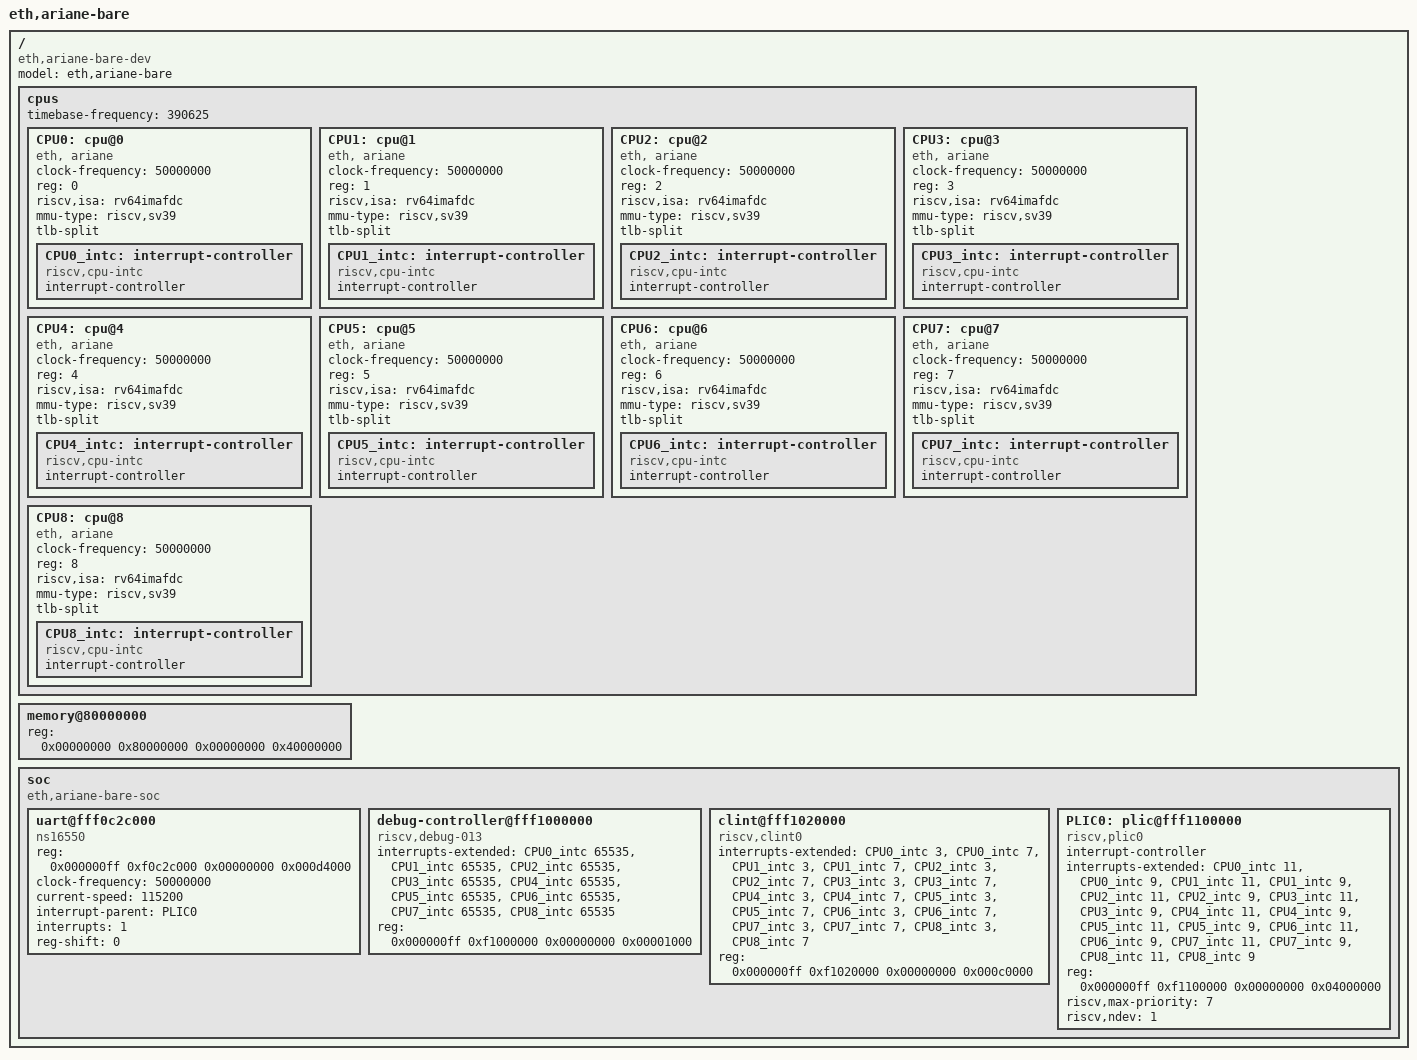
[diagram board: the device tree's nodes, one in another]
// DTS generated with gen_riscv_dts(...)
// OpenPiton + Ariane framework
// Date: Nov 05 2021 09:18:08

/dts-v1/;

/ {
    #address-cells = <2>;
    #size-cells = <2>;
    compatible = "eth,ariane-bare-dev";
    model = "eth,ariane-bare";
    // TODO: interrupt-based UART is currently very slow
    // with this configuration. this needs to be fixed.
    // chosen {
    //     stdout-path = "/soc/uart@fff0c2c000:115200";
    // };
    cpus {
        #address-cells = <1>;
        #size-cells = <0>;
        timebase-frequency = <390625>;
    
        CPU0: cpu@0 {
            clock-frequency = <50000000>;
            device_type = "cpu";
            reg = <0>;
            status = "okay";
            compatible = "eth, ariane", "riscv";
            riscv,isa = "rv64imafdc";
            mmu-type = "riscv,sv39";
            tlb-split;
            // HLIC - hart local interrupt controller
            CPU0_intc: interrupt-controller {
                #interrupt-cells = <1>;
                interrupt-controller;
                compatible = "riscv,cpu-intc";
            };
        };
        
        CPU1: cpu@1 {
            clock-frequency = <50000000>;
            device_type = "cpu";
            reg = <1>;
            status = "okay";
            compatible = "eth, ariane", "riscv";
            riscv,isa = "rv64imafdc";
            mmu-type = "riscv,sv39";
            tlb-split;
            // HLIC - hart local interrupt controller
            CPU1_intc: interrupt-controller {
                #interrupt-cells = <1>;
                interrupt-controller;
                compatible = "riscv,cpu-intc";
            };
        };
        
        CPU2: cpu@2 {
            clock-frequency = <50000000>;
            device_type = "cpu";
            reg = <2>;
            status = "okay";
            compatible = "eth, ariane", "riscv";
            riscv,isa = "rv64imafdc";
            mmu-type = "riscv,sv39";
            tlb-split;
            // HLIC - hart local interrupt controller
            CPU2_intc: interrupt-controller {
                #interrupt-cells = <1>;
                interrupt-controller;
                compatible = "riscv,cpu-intc";
            };
        };
        
        CPU3: cpu@3 {
            clock-frequency = <50000000>;
            device_type = "cpu";
            reg = <3>;
            status = "okay";
            compatible = "eth, ariane", "riscv";
            riscv,isa = "rv64imafdc";
            mmu-type = "riscv,sv39";
            tlb-split;
            // HLIC - hart local interrupt controller
            CPU3_intc: interrupt-controller {
                #interrupt-cells = <1>;
                interrupt-controller;
                compatible = "riscv,cpu-intc";
            };
        };
        
        CPU4: cpu@4 {
            clock-frequency = <50000000>;
            device_type = "cpu";
            reg = <4>;
            status = "okay";
            compatible = "eth, ariane", "riscv";
            riscv,isa = "rv64imafdc";
            mmu-type = "riscv,sv39";
            tlb-split;
            // HLIC - hart local interrupt controller
            CPU4_intc: interrupt-controller {
                #interrupt-cells = <1>;
                interrupt-controller;
                compatible = "riscv,cpu-intc";
            };
        };
        
        CPU5: cpu@5 {
            clock-frequency = <50000000>;
            device_type = "cpu";
            reg = <5>;
            status = "okay";
            compatible = "eth, ariane", "riscv";
            riscv,isa = "rv64imafdc";
            mmu-type = "riscv,sv39";
            tlb-split;
            // HLIC - hart local interrupt controller
            CPU5_intc: interrupt-controller {
                #interrupt-cells = <1>;
                interrupt-controller;
                compatible = "riscv,cpu-intc";
            };
        };
        
        CPU6: cpu@6 {
            clock-frequency = <50000000>;
            device_type = "cpu";
            reg = <6>;
            status = "okay";
            compatible = "eth, ariane", "riscv";
            riscv,isa = "rv64imafdc";
            mmu-type = "riscv,sv39";
            tlb-split;
            // HLIC - hart local interrupt controller
            CPU6_intc: interrupt-controller {
                #interrupt-cells = <1>;
                interrupt-controller;
                compatible = "riscv,cpu-intc";
            };
        };
        
        CPU7: cpu@7 {
            clock-frequency = <50000000>;
            device_type = "cpu";
            reg = <7>;
            status = "okay";
            compatible = "eth, ariane", "riscv";
            riscv,isa = "rv64imafdc";
            mmu-type = "riscv,sv39";
            tlb-split;
            // HLIC - hart local interrupt controller
            CPU7_intc: interrupt-controller {
                #interrupt-cells = <1>;
                interrupt-controller;
                compatible = "riscv,cpu-intc";
            };
        };
        
        CPU8: cpu@8 {
            clock-frequency = <50000000>;
            device_type = "cpu";
            reg = <8>;
            status = "okay";
            compatible = "eth, ariane", "riscv";
            riscv,isa = "rv64imafdc";
            mmu-type = "riscv,sv39";
            tlb-split;
            // HLIC - hart local interrupt controller
            CPU8_intc: interrupt-controller {
                #interrupt-cells = <1>;
                interrupt-controller;
                compatible = "riscv,cpu-intc";
            };
        };
        
    };
    
    memory@80000000 {
        device_type = "memory";
        reg = < 0x00000000 0x80000000 0x00000000 0x40000000 >;
    };
            
    soc {
        #address-cells = <2>;
        #size-cells = <2>;
        compatible = "eth,ariane-bare-soc", "simple-bus";
        ranges;
    
        uart@fff0c2c000 {
            compatible = "ns16550";
            reg = < 0x000000ff 0xf0c2c000 0x00000000 0x000d4000 >;
            clock-frequency = <50000000>;
            current-speed = <115200>;
            interrupt-parent = <&PLIC0>;
            interrupts = <1>;
            reg-shift = <0>; // regs are spaced on 8 bit boundary (modified from Xilinx UART16550 to be ns16550 compatible)
        };
            
        debug-controller@fff1000000 {
            compatible = "riscv,debug-013";
            interrupts-extended = <&CPU0_intc 65535 &CPU1_intc 65535 &CPU2_intc 65535 &CPU3_intc 65535 &CPU4_intc 65535 &CPU5_intc 65535 &CPU6_intc 65535 &CPU7_intc 65535 &CPU8_intc 65535 >;
            reg = < 0x000000ff 0xf1000000 0x00000000 0x00001000 >;
            reg-names = "control";
        };
            
        clint@fff1020000 {
            compatible = "riscv,clint0";
            interrupts-extended = <&CPU0_intc 3 &CPU0_intc 7 &CPU1_intc 3 &CPU1_intc 7 &CPU2_intc 3 &CPU2_intc 7 &CPU3_intc 3 &CPU3_intc 7 &CPU4_intc 3 &CPU4_intc 7 &CPU5_intc 3 &CPU5_intc 7 &CPU6_intc 3 &CPU6_intc 7 &CPU7_intc 3 &CPU7_intc 7 &CPU8_intc 3 &CPU8_intc 7 >;
            reg = < 0x000000ff 0xf1020000 0x00000000 0x000c0000 >;
            reg-names = "control";
        };
            
        PLIC0: plic@fff1100000 {
            #address-cells = <0>;
            #interrupt-cells = <1>;
            compatible = "riscv,plic0";
            interrupt-controller;
            interrupts-extended = <&CPU0_intc 11 &CPU0_intc 9 &CPU1_intc 11 &CPU1_intc 9 &CPU2_intc 11 &CPU2_intc 9 &CPU3_intc 11 &CPU3_intc 9 &CPU4_intc 11 &CPU4_intc 9 &CPU5_intc 11 &CPU5_intc 9 &CPU6_intc 11 &CPU6_intc 9 &CPU7_intc 11 &CPU7_intc 9 &CPU8_intc 11 &CPU8_intc 9 >;
            reg = < 0x000000ff 0xf1100000 0x00000000 0x04000000 >;
            riscv,max-priority = <7>;
            riscv,ndev = <1>;
        };
            
    };
};
    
